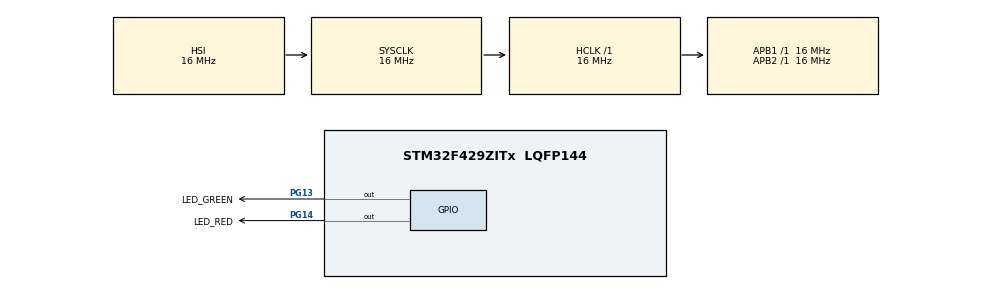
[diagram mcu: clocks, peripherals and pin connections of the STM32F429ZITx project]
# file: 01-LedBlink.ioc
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Mcu.Family=STM32F4
Mcu.Name=STM32F429ZITx
Mcu.Package=LQFP144
NVIC.PriorityGroup=NVIC_PRIORITYGROUP_0
PA13.Mode=Serial_Wire
PA13.Signal=SYS_JTMS-SWDIO
PA14.Mode=Serial_Wire
PA14.Signal=SYS_JTCK-SWCLK
PG13.GPIO_Label=LED_GREEN
PG13.Signal=GPIO_Output
PG14.GPIO_Label=LED_RED
PG14.Signal=GPIO_Output
ProjectManager.HeapSize=0x200
ProjectManager.StackSize=0x400
ProjectManager.TargetToolchain=EWARM V8.50
RCC.48MHZClocksFreq_Value=20571428.57142857
RCC.AHBFreq_Value=16000000
RCC.APB1Freq_Value=16000000
RCC.APB1TimFreq_Value=16000000
RCC.APB2Freq_Value=16000000
RCC.APB2TimFreq_Value=16000000
RCC.CortexFreq_Value=16000000
RCC.HCLKFreq_Value=16000000
RCC.HSE_VALUE=8000000
RCC.HSI_VALUE=16000000
RCC.LSE_VALUE=32768
RCC.LockedElements=EthernetPtpOutput
RCC.PLLM=8
RCC.PLLN=72
RCC.PLLP=RCC_PLLP_DIV6
RCC.PLLQ=7
RCC.SYSCLKFreq_VALUE=16000000
RCC.VCOOutputFreq_Value=144000000
board=STM32F429I-DISC1

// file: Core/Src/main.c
/* USER CODE BEGIN Header */
/**
  ******************************************************************************
  * @file           : main.c
  * @brief          : Main program body
  ******************************************************************************
  * @attention
  *
  * Copyright (c) 2025 STMicroelectronics.
  * All rights reserved.
  *
  * This software is licensed under terms that can be found in the LICENSE file
  * in the root directory of this software component.
  * If no LICENSE file comes with this software, it is provided AS-IS.
  *
  ******************************************************************************
  */
/* USER CODE END Header */
#include "main.h"

/* USER CODE BEGIN PM */
#define LED_1_TASK_TIME       500u    /* In milliseconds */
#define LED_2_TASK_TIME       250u    /* In milliseconds */
#define USER_BTN_TASK_TIME    10u     /* In milliseconds */
#define SERIAL_TX_TIME        1000u   /* In milliseconds */
/* USER CODE END PM */

/* USER CODE BEGIN PV */
static uint8_t led_1_state = FALSE;
static uint8_t led_2_state = FALSE;
static uint32_t led_1_timestamp = 0u;
static uint32_t led_2_timestamp = 0u;
static uint32_t user_btn_timestamp = 0u;
static uint32_t usart2_tx_timestamp = 0u;

static const uint8_t msg1[] = "Getting Started with STM32\r\n";
static const uint8_t msg2[] = "Hi, Transmitting from STM32F4\r\n";
static uint8_t rx_data = 0u;
/* USER CODE END PV */

void SystemClock_Config(void);
static void MX_GPIO_Init(void);

int main(void)
{

  /* MCU Configuration--------------------------------------------------------*/

  /* Reset of all peripherals, Initializes the Flash interface and the Systick. */
  HAL_Init();

  /* Configure the system clock */
  SystemClock_Config();

  /* Initialize all configured peripherals */
  MX_GPIO_Init();

  /* Infinite loop */
  while (1)
  {

    /* USER CODE BEGIN 3 */
    /* Method-1: Simple Way of Blinking */
    // HAL_GPIO_TogglePin( LED_RED_GPIO_Port, LED_RED_Pin);
    // HAL_GPIO_TogglePin( LED_GREEN_GPIO_Port, LED_GREEN_Pin);
    // HAL_Delay(500);
    /* Method-2: With the help of SysTick timers*/
    /* Task for Led 1 */
    if( HAL_GetTick() - led_1_timestamp > LED_1_TASK_TIME )
    {
      led_1_timestamp = HAL_GetTick();
      if( led_1_state )
      {
        led_1_state = FALSE;
        /* Setting Pin High will turn off the Led */
        HAL_GPIO_WritePin( LED_RED_GPIO_Port, LED_RED_Pin, GPIO_PIN_RESET );
      }
      else
      {
        led_1_state = TRUE;
        /* Setting Pin Low will turn on the Led */
        HAL_GPIO_WritePin( LED_RED_GPIO_Port, LED_RED_Pin, GPIO_PIN_SET );
      }
    }
    /* Task for Led 2 */
    if( HAL_GetTick() - led_2_timestamp > LED_2_TASK_TIME )
    {
      led_2_timestamp = HAL_GetTick();
      if( led_2_state )
      {
        led_2_state = FALSE;
        /* Setting Pin High will turn off the Led */
        HAL_GPIO_WritePin( LED_GREEN_GPIO_Port, LED_GREEN_Pin, GPIO_PIN_RESET );
      }
      else
      {
        led_2_state = TRUE;
        /* Setting Pin Low will turn on the Led */
        HAL_GPIO_WritePin( LED_GREEN_GPIO_Port, LED_GREEN_Pin, GPIO_PIN_SET );
      }
    }
  }
  /* USER CODE END 3 */
}

void SystemClock_Config(void)
{
  RCC_OscInitTypeDef RCC_OscInitStruct = {0};
  RCC_ClkInitTypeDef RCC_ClkInitStruct = {0};

  /** Configure the main internal regulator output voltage
  */
  __HAL_RCC_PWR_CLK_ENABLE();
  __HAL_PWR_VOLTAGESCALING_CONFIG(PWR_REGULATOR_VOLTAGE_SCALE3);

  /** Initializes the RCC Oscillators according to the specified parameters
  * in the RCC_OscInitTypeDef structure.
  */
  RCC_OscInitStruct.OscillatorType = RCC_OSCILLATORTYPE_HSI;
  RCC_OscInitStruct.HSIState = RCC_HSI_ON;
  RCC_OscInitStruct.HSICalibrationValue = RCC_HSICALIBRATION_DEFAULT;
  RCC_OscInitStruct.PLL.PLLState = RCC_PLL_NONE;
  if (HAL_RCC_OscConfig(&RCC_OscInitStruct) != HAL_OK)
  {
    Error_Handler();
  }

  /** Initializes the CPU, AHB and APB buses clocks
  */
  RCC_ClkInitStruct.ClockType = RCC_CLOCKTYPE_HCLK|RCC_CLOCKTYPE_SYSCLK
                              |RCC_CLOCKTYPE_PCLK1|RCC_CLOCKTYPE_PCLK2;
  RCC_ClkInitStruct.SYSCLKSource = RCC_SYSCLKSOURCE_HSI;
  RCC_ClkInitStruct.AHBCLKDivider = RCC_SYSCLK_DIV1;
  RCC_ClkInitStruct.APB1CLKDivider = RCC_HCLK_DIV1;
  RCC_ClkInitStruct.APB2CLKDivider = RCC_HCLK_DIV1;

  if (HAL_RCC_ClockConfig(&RCC_ClkInitStruct, FLASH_LATENCY_0) != HAL_OK)
  {
    Error_Handler();
  }
}

static void MX_GPIO_Init(void)
{
  GPIO_InitTypeDef GPIO_InitStruct = {0};

  /* GPIO Ports Clock Enable */
  __HAL_RCC_GPIOA_CLK_ENABLE();
  __HAL_RCC_GPIOG_CLK_ENABLE();

  /*Configure GPIO pin Output Level */
  HAL_GPIO_WritePin(GPIOG, LED_GREEN_Pin|LED_RED_Pin, GPIO_PIN_RESET);

  /*Configure GPIO pins : LED_GREEN_Pin LED_RED_Pin */
  GPIO_InitStruct.Pin = LED_GREEN_Pin|LED_RED_Pin;
  GPIO_InitStruct.Mode = GPIO_MODE_OUTPUT_PP;
  GPIO_InitStruct.Pull = GPIO_NOPULL;
  GPIO_InitStruct.Speed = GPIO_SPEED_FREQ_LOW;
  HAL_GPIO_Init(GPIOG, &GPIO_InitStruct);

}

void Error_Handler(void)
{
  __disable_irq();
  while (1)
  {
  }
}
